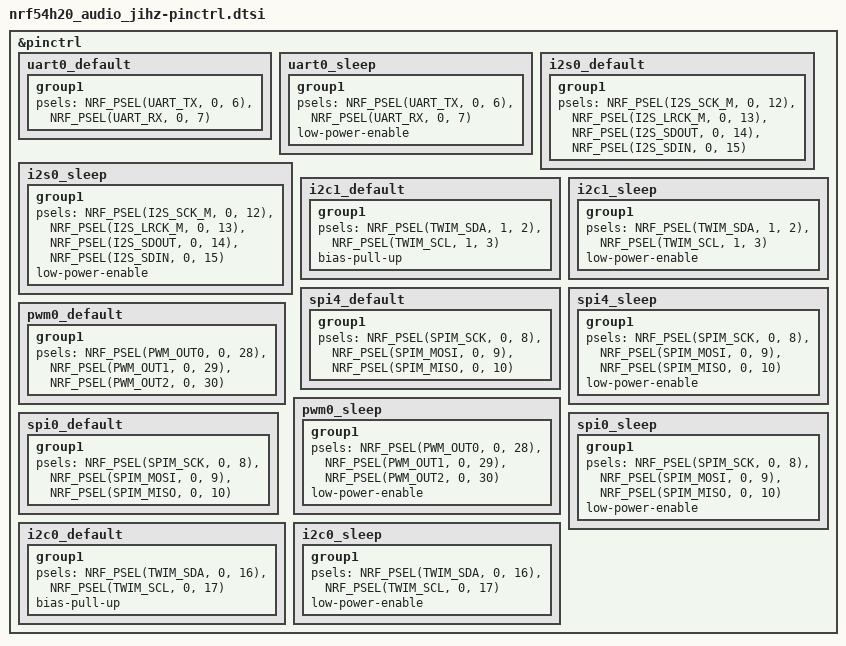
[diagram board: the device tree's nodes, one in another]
/*
 * Copyright (c) 2024 Nordic Semiconductor ASA
 * SPDX-License-Identifier: Apache-2.0
 */

#include <zephyr/dt-bindings/pinctrl/nrf54h20-pinctrl.h>

&pinctrl {
    /* UART0 default configurations like nRF5340 Audio DK */
    uart0_default: uart0_default {
        group1 {
            psels = <NRF_PSEL(UART_TX, 0, 20)>,
                    <NRF_PSEL(UART_RX, 0, 22)>,
                    <NRF_PSEL(UART_RTS, 0, 19)>,
                    <NRF_PSEL(UART_CTS, 0, 21)>;
        };
    };

    uart0_sleep: uart0_sleep {
        group1 {
            psels = <NRF_PSEL(UART_TX, 0, 20)>,
                    <NRF_PSEL(UART_RX, 0, 22)>,
                    <NRF_PSEL(UART_RTS, 0, 19)>,
                    <NRF_PSEL(UART_CTS, 0, 21)>;
            low-power-enable;
        };
    };

    /* I2S configurations like nRF5340 Audio DK */
    i2s0_default: i2s0_default {
        group1 {
            psels = <NRF_PSEL(I2S_SCK_M, 0, 12)>,
                    <NRF_PSEL(I2S_LRCK_M, 0, 13)>,
                    <NRF_PSEL(I2S_SDOUT, 0, 14)>,
                    <NRF_PSEL(I2S_SDIN, 0, 15)>;
        };
    };

    i2s0_sleep: i2s0_sleep {
        group1 {
            psels = <NRF_PSEL(I2S_SCK_M, 0, 12)>,
                    <NRF_PSEL(I2S_LRCK_M, 0, 13)>,
                    <NRF_PSEL(I2S_SDOUT, 0, 14)>,
                    <NRF_PSEL(I2S_SDIN, 0, 15)>;
            low-power-enable;
        };
    };

    /* I2C configurations like nRF5340 Audio DK */
    i2c1_default: i2c1_default {
        group1 {
            psels = <NRF_PSEL(TWIM_SDA, 1, 2)>,
                    <NRF_PSEL(TWIM_SCL, 1, 3)>;
            bias-pull-up;
        };
    };

    i2c1_sleep: i2c1_sleep {
        group1 {
            psels = <NRF_PSEL(TWIM_SDA, 1, 2)>,
                    <NRF_PSEL(TWIM_SCL, 1, 3)>;
            low-power-enable;
        };
    };

    /* SPI configurations like nRF5340 Audio DK */
    spi4_default: spi4_default {
        group1 {
            psels = <NRF_PSEL(SPIM_SCK, 0, 8)>,
                    <NRF_PSEL(SPIM_MOSI, 0, 9)>,
                    <NRF_PSEL(SPIM_MISO, 0, 10)>;
        };
    };

    spi4_sleep: spi4_sleep {
        group1 {
            psels = <NRF_PSEL(SPIM_SCK, 0, 8)>,
                    <NRF_PSEL(SPIM_MOSI, 0, 9)>,
                    <NRF_PSEL(SPIM_MISO, 0, 10)>;
            low-power-enable;
        };
    };

    /* PWM configurations like nRF5340 Audio DK */
    pwm0_default: pwm0_default {
        group1 {
            psels = <NRF_PSEL(PWM_OUT0, 0, 28)>,
                    <NRF_PSEL(PWM_OUT1, 0, 29)>,
                    <NRF_PSEL(PWM_OUT2, 0, 30)>;
        };
    };

    pwm0_sleep: pwm0_sleep {
        group1 {
            psels = <NRF_PSEL(PWM_OUT0, 0, 28)>,
                    <NRF_PSEL(PWM_OUT1, 0, 29)>,
                    <NRF_PSEL(PWM_OUT2, 0, 30)>;
            low-power-enable;
        };
    };
    /* UART0 default configurations */
    uart0_default: uart0_default {
        group1 {
            psels = <NRF_PSEL(UART_TX, 0, 6)>,
                    <NRF_PSEL(UART_RX, 0, 7)>;
        };
    };

    uart0_sleep: uart0_sleep {
        group1 {
            psels = <NRF_PSEL(UART_TX, 0, 6)>,
                    <NRF_PSEL(UART_RX, 0, 7)>;
            low-power-enable;
        };
    };

    /* I2S configurations for audio */
    i2s0_default: i2s0_default {
        group1 {
            psels = <NRF_PSEL(I2S_SCK_M, 0, 12)>,
                    <NRF_PSEL(I2S_LRCK_M, 0, 13)>,
                    <NRF_PSEL(I2S_SDOUT, 0, 14)>,
                    <NRF_PSEL(I2S_SDIN, 0, 15)>;
        };
    };

    /* SPI configurations for external flash/sensors */
    spi0_default: spi0_default {
        group1 {
            psels = <NRF_PSEL(SPIM_SCK, 0, 8)>,
                    <NRF_PSEL(SPIM_MOSI, 0, 9)>,
                    <NRF_PSEL(SPIM_MISO, 0, 10)>;
        };
    };

    spi0_sleep: spi0_sleep {
        group1 {
            psels = <NRF_PSEL(SPIM_SCK, 0, 8)>,
                    <NRF_PSEL(SPIM_MOSI, 0, 9)>,
                    <NRF_PSEL(SPIM_MISO, 0, 10)>;
            low-power-enable;
        };
    };

    /* I2C configurations for audio codec and sensors */
    i2c0_default: i2c0_default {
        group1 {
            psels = <NRF_PSEL(TWIM_SDA, 0, 16)>,
                    <NRF_PSEL(TWIM_SCL, 0, 17)>;
            bias-pull-up;
        };
    };

    i2c0_sleep: i2c0_sleep {
        group1 {
            psels = <NRF_PSEL(TWIM_SDA, 0, 16)>,
                    <NRF_PSEL(TWIM_SCL, 0, 17)>;
            low-power-enable;
        };
    };
};
